AUTOSAR XML (schema 4-3-1)
standard types defined: uint8, uint8_DataConstr
package /ComponentTypes
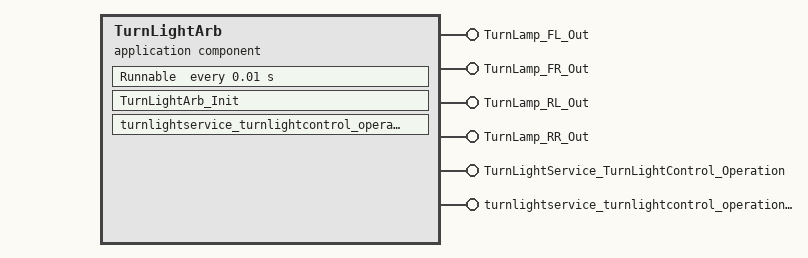
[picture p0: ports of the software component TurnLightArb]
  application sw component type TurnLightArb
    6 x provide port:
      TurnLamp_FL_Out: nonqueued-sender-com-spec{data-element=TurnLamp_FL_Out/Signal, init-value=ComSpecf480ce3d_8ef63310310169bd:0}, provided-interface=TurnLamp_FL_Out
      TurnLamp_FR_Out: nonqueued-sender-com-spec{data-element=TurnLamp_FR_Out/Signal, init-value=ComSpec0b54c753_e62dd27419b61e61:0}, provided-interface=TurnLamp_FR_Out
      TurnLamp_RL_Out: nonqueued-sender-com-spec{data-element=TurnLamp_RL_Out/Signal, init-value=ComSpec9d24c0bf_0aa4a7df2454514f:0}, provided-interface=TurnLamp_RL_Out
      TurnLamp_RR_Out: nonqueued-sender-com-spec{data-element=TurnLamp_RR_Out/Signal, init-value=ComSpec368125c0_7e3a491713f4b637:0}, provided-interface=TurnLamp_RR_Out
      TurnLightService_TurnLightControl_Operation: provided-interface=TurnLightService_TurnLightControl_Operation
      turnlightservice_turnlightcontrol_operation_operation_1: server-com-spec{operation=turnlightservice_turnlightcontrol_operation_operation_1, queue-length=1}, provided-interface=turnlightservice_turnlightcontrol_operation_operation_1
    behavior TurnLightArb_InternalBehavior: data-type-mapping=TurnLightArbDataTypeMappingsSet, handle-termination-and-restart=NO-SUPPORT
      timing event TMT_Runnable: start-on-event=Runnable, period=0.01
      operation invoked event Event_turnlightservice_turnlightcontrol_operation_operation_1: start-on-event=turnlightservice_turnlightcontrol_operation_operation_1, operation=turnlightservice_turnlightcontrol_operation_operation_1.turnlightservice_turnlightcontrol_operation_operation_1
      runnable Runnable
        data-send-points:
          4 x access:
            OUT_TurnLamp_FL_Out_Signal: accessed-variable=TurnLamp_FL_Out.Signal
            OUT_TurnLamp_FR_Out_Signal: accessed-variable=TurnLamp_FR_Out.Signal
            OUT_TurnLamp_RL_Out_Signal: accessed-variable=TurnLamp_RL_Out.Signal
            OUT_TurnLamp_RR_Out_Signal: accessed-variable=TurnLamp_RR_Out.Signal
      runnable TurnLightArb_Init
      runnable turnlightservice_turnlightcontrol_operation_operation_1
package /DataTypes
  impl type TurnLightService_Ctrl_Oeration: category=STRUCTURE
    7 x element, all with category=TYPE_REFERENCE, implementation-data-type=uint8:
      TurnLightPosition
      TurnLightOnOff
      TurnLightDutyCycle
      TurnLightCycle
      TurnLightTimes
      TurnLightNum
      TurnLightPriority
package /DataTypes/CompuMethods
  compu method TurnLightOnOff: 0=NOREQUEST, 1=OFF, 2=ON
  compu method TurnLightPosition: 0=NOREQUEST, 1=LEFT, 2=RIGHT, 3=ALL, 4=FRONT_LEFT, 5=MIDDLE_LEFT, 6=REAR_LEFT, 7=FRONT_RIGHT, 8=MIDDLE_RIGHT, 9=REAR_RIGHT
package /PortInterfaces
  client server interface TurnLightService_TurnLightControl_Operation
    operation Operation
      arg TurnLightCtrlPara: category=STRUCTURE, sw-calibration-access=READ-WRITE, type=TurnLightService, direction=IN
  4 x sender receiver interface:
    TurnLamp_FL_Out: invalidation-policy{data-element=TurnLamp_FL_Out/Signal, handle-invalid=DONT-INVALIDATE}
      data Signal: category=VALUE, type=uint8
    TurnLamp_FR_Out: invalidation-policy{data-element=TurnLamp_FR_Out/Signal, handle-invalid=DONT-INVALIDATE}
      data Signal: category=VALUE, type=uint8
    TurnLamp_RL_Out: invalidation-policy{data-element=TurnLamp_RL_Out/Signal, handle-invalid=DONT-INVALIDATE}
      data Signal: category=VALUE, type=uint8
    TurnLamp_RR_Out: invalidation-policy{data-element=TurnLamp_RR_Out/Signal, handle-invalid=DONT-INVALIDATE}
      data Signal: category=VALUE, type=uint8
